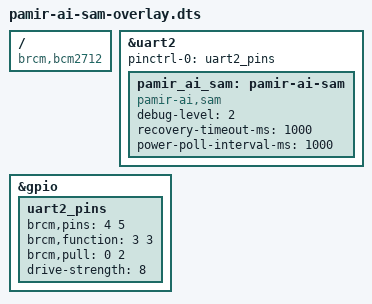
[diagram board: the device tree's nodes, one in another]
// SPDX-License-Identifier: GPL-2.0-only
/*
 * Device Tree overlay for Pamir AI SAM Module
 *
 * Copyright (C) 2025 Pamir AI Incorporated.
 */

/dts-v1/;
/plugin/;

/* Using numeric values directly since #define not supported in overlays */

/ {
	compatible = "brcm,bcm2712";

	fragment@0 {
		target = <&uart2>;
		__overlay__ {
			status = "okay";
			pinctrl-names = "default";
			pinctrl-0 = <&uart2_pins>;
			/delete-property/ dmas;
			/delete-property/ dma-names;
		};
	};

	fragment@1 {
		target = <&uart2>;
		__overlay__ {
			pamir_ai_sam: pamir-ai-sam {
				compatible = "pamir-ai,sam";
				status = "okay";
				debug-level = <2>;
				recovery-timeout-ms = <1000>;
				power-poll-interval-ms = <1000>; /* 0 means no polling */
				/* ack-required; // Disabled to prevent ping spam */
			};
		};
	};

	/* Configure UART2 pins */
	fragment@2 {
		target = <&gpio>;
		__overlay__ {
			uart2_pins: uart2_pins {
				brcm,pins = <4 5>; /* TX on GPIO4, RX on GPIO5 */
				brcm,function = <3 3>; /* ALT4 = 3 for BCM2712 */
				brcm,pull = <0 2>; /* TX=OFF, RX=UP */
				drive-strength = <8>;
			};
		};
	};

	__overrides__ {
		debug_level = <&pamir_ai_sam>,"debug-level:0";
		recovery_timeout = <&pamir_ai_sam>,"recovery-timeout-ms:0";
		power_poll_interval = <&pamir_ai_sam>,"power-poll-interval-ms:0";
		ack_required = <&pamir_ai_sam>,"ack-required?";
	};
}; 
